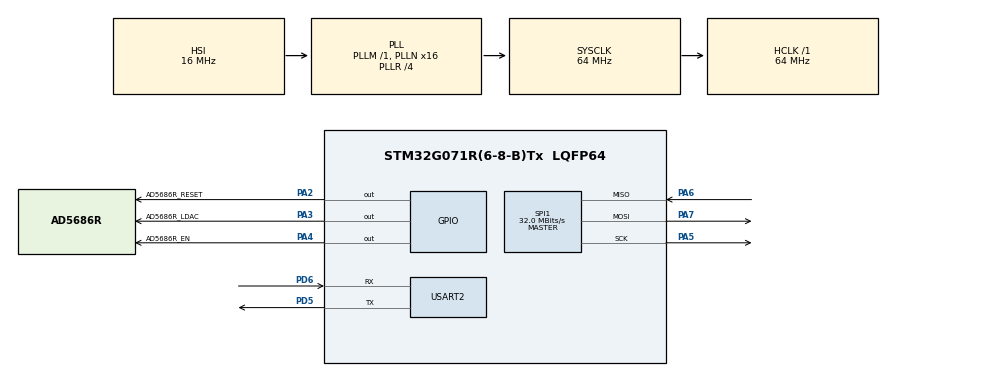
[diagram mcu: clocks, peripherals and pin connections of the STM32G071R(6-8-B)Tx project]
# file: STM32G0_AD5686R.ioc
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Mcu.Family=STM32G0
Mcu.Name=STM32G071R(6-8-B)Tx
Mcu.Package=LQFP64
PA2.GPIO_Label=AD5686R_RESET
PA2.GPIO_PuPd=GPIO_PULLUP
PA2.GPIO_Speed=GPIO_SPEED_FREQ_VERY_HIGH
PA2.PinState=GPIO_PIN_SET
PA2.Signal=GPIO_Output
PA3.GPIO_Label=AD5686R_LDAC
PA3.GPIO_PuPd=GPIO_PULLUP
PA3.GPIO_Speed=GPIO_SPEED_FREQ_VERY_HIGH
PA3.PinState=GPIO_PIN_SET
PA3.Signal=GPIO_Output
PA4.GPIO_Label=AD5686R_EN
PA4.GPIO_PuPd=GPIO_PULLUP
PA4.GPIO_Speed=GPIO_SPEED_FREQ_VERY_HIGH
PA4.PinState=GPIO_PIN_SET
PA4.Signal=GPIO_Output
PA5.GPIO_Speed=GPIO_SPEED_FREQ_VERY_HIGH
PA5.Mode=Full_Duplex_Master
PA5.Signal=SPI1_SCK
PA6.GPIO_Speed=GPIO_SPEED_FREQ_VERY_HIGH
PA6.Mode=Full_Duplex_Master
PA6.Signal=SPI1_MISO
PA7.GPIO_Speed=GPIO_SPEED_FREQ_VERY_HIGH
PA7.Mode=Full_Duplex_Master
PA7.Signal=SPI1_MOSI
PC14-OSC32_IN\ (PC14).Mode=LSE-External-Oscillator
PC14-OSC32_IN\ (PC14).Signal=RCC_OSC32_IN
PC15-OSC32_OUT\ (PC15).Mode=LSE-External-Oscillator
PC15-OSC32_OUT\ (PC15).Signal=RCC_OSC32_OUT
PD5.GPIO_Speed=GPIO_SPEED_FREQ_VERY_HIGH
PD5.Mode=Asynchronous
PD5.Signal=USART2_TX
PD6.GPIO_Speed=GPIO_SPEED_FREQ_VERY_HIGH
PD6.Mode=Asynchronous
PD6.Signal=USART2_RX
PF0-OSC_IN\ (PF0).Mode=HSE-External-Oscillator
PF0-OSC_IN\ (PF0).Signal=RCC_OSC_IN
PF1-OSC_OUT\ (PF1).Mode=HSE-External-Oscillator
PF1-OSC_OUT\ (PF1).Signal=RCC_OSC_OUT
ProjectManager.HeapSize=0x200
ProjectManager.StackSize=0x400
ProjectManager.TargetToolchain=MDK-ARM V5.27
RCC.ADCFreq_Value=64000000
RCC.AHBFreq_Value=64000000
RCC.CortexFreq_Value=64000000
RCC.EXTERNAL_CLOCK_VALUE=48000
RCC.HCLKFreq_Value=64000000
RCC.HSE_VALUE=8000000
RCC.HSI_VALUE=16000000
RCC.PLLN=16
RCC.PLLR=RCC_PLLR_DIV4
RCC.SYSCLKFreq_VALUE=64000000
RCC.SYSCLKSource=RCC_SYSCLKSOURCE_PLLCLK
RCC.VCOOutputFreq_Value=256000000
SPI1.BaudRatePrescaler=SPI_BAUDRATEPRESCALER_2
SPI1.CalculateBaudRate=32.0 MBits/s
SPI1.DataSize=SPI_DATASIZE_8BIT
SPI1.Direction=SPI_DIRECTION_2LINES
SPI1.FirstBit=SPI_FIRSTBIT_MSB
SPI1.Mode=SPI_MODE_MASTER
SPI1.VirtualType=VM_MASTER
USART2.VirtualMode-Asynchronous=VM_ASYNC
VP_SYS_VS_DBSignals.Mode=DisableDeadBatterySignals
board=custom

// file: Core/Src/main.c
/* USER CODE BEGIN Header */
/**
  ******************************************************************************
  * @file           : main.c
  * @brief          : Main program body
  ******************************************************************************
  * @attention
  *
  * <h2><center>&copy; Copyright (c) 2021 STMicroelectronics.
  * All rights reserved.</center></h2>
  *
  * This software component is licensed by ST under BSD 3-Clause license,
  * the "License"; You may not use this file except in compliance with the
  * License. You may obtain a copy of the License at:
  *                        opensource.org/licenses/BSD-3-Clause
  *
  ******************************************************************************
  */
/* USER CODE END Header */
#include "main.h"
#include "spi.h"
#include "usart.h"
#include "gpio.h"
#include "AD5686_5_4R.h"

void SystemClock_Config(void);

int main(void)
{

  /* MCU Configuration--------------------------------------------------------*/

  /* Reset of all peripherals, Initializes the Flash interface and the Systick. */
  HAL_Init();

  /* Configure the system clock */
  SystemClock_Config();

  /* Initialize all configured peripherals */
  MX_GPIO_Init();
  MX_SPI1_Init();
  MX_USART2_UART_Init();
  /* USER CODE BEGIN 2 */
	AD5686x_Init();
	AD568x_write_V(&DAC1_AD5686,Aisle_A,4.123);
  /* USER CODE END 2 */

  /* Infinite loop */
  while (1)
  {

    /* USER CODE BEGIN 3 */
		/*
		AD568x_set_shift_reg(&DAC1_AD5686,Aisle_A,0);
		AD568x_set_shift_reg(&DAC1_AD5686,Aisle_B,0);
		AD568x_Renew_LDAC(&DAC1_AD5686);
		__nop();
		AD568x_set_shift_reg(&DAC1_AD5686,Aisle_A,65535);
		AD568x_set_shift_reg(&DAC1_AD5686,Aisle_B,65535);
		AD568x_Renew_LDAC(&DAC1_AD5686);
		__nop();
		*/
		/*
		for(int i=500;i<65000;i=i+200)
		{
			AD568x_set_shift_reg(&DAC1_AD5686,Aisle_A,i);
			AD568x_set_shift_reg(&DAC1_AD5686,Aisle_B,i);
			AD568x_Renew_LDAC(&DAC1_AD5686);
			//AD568x_update_register(&DAC1_AD5686,Aisle_A);
			//AD568x_update_register(&DAC1_AD5686,Aisle_B);
		}
		for(int a=65000;a>500;a=a-200)
		{
			AD568x_set_shift_reg(&DAC1_AD5686,Aisle_A,a);
			AD568x_set_shift_reg(&DAC1_AD5686,Aisle_B,a);
			AD568x_Renew_LDAC(&DAC1_AD5686);
			//AD568x_update_register(&DAC1_AD5686,Aisle_A);
			//AD568x_update_register(&DAC1_AD5686,Aisle_B);
		}
		*/

  /* USER CODE END 3 */
}
}

void SystemClock_Config(void)
{
  RCC_OscInitTypeDef RCC_OscInitStruct = {0};
  RCC_ClkInitTypeDef RCC_ClkInitStruct = {0};
  RCC_PeriphCLKInitTypeDef PeriphClkInit = {0};

  /** Configure the main internal regulator output voltage
  */
  HAL_PWREx_ControlVoltageScaling(PWR_REGULATOR_VOLTAGE_SCALE1);
  /** Initializes the RCC Oscillators according to the specified parameters
  * in the RCC_OscInitTypeDef structure.
  */
  RCC_OscInitStruct.OscillatorType = RCC_OSCILLATORTYPE_HSI;
  RCC_OscInitStruct.HSIState = RCC_HSI_ON;
  RCC_OscInitStruct.HSIDiv = RCC_HSI_DIV1;
  RCC_OscInitStruct.HSICalibrationValue = RCC_HSICALIBRATION_DEFAULT;
  RCC_OscInitStruct.PLL.PLLState = RCC_PLL_ON;
  RCC_OscInitStruct.PLL.PLLSource = RCC_PLLSOURCE_HSI;
  RCC_OscInitStruct.PLL.PLLM = RCC_PLLM_DIV1;
  RCC_OscInitStruct.PLL.PLLN = 16;
  RCC_OscInitStruct.PLL.PLLP = RCC_PLLP_DIV2;
  RCC_OscInitStruct.PLL.PLLQ = RCC_PLLQ_DIV2;
  RCC_OscInitStruct.PLL.PLLR = RCC_PLLR_DIV4;
  if (HAL_RCC_OscConfig(&RCC_OscInitStruct) != HAL_OK)
  {
    Error_Handler();
  }
  /** Initializes the CPU, AHB and APB buses clocks
  */
  RCC_ClkInitStruct.ClockType = RCC_CLOCKTYPE_HCLK|RCC_CLOCKTYPE_SYSCLK
                              |RCC_CLOCKTYPE_PCLK1;
  RCC_ClkInitStruct.SYSCLKSource = RCC_SYSCLKSOURCE_PLLCLK;
  RCC_ClkInitStruct.AHBCLKDivider = RCC_SYSCLK_DIV1;
  RCC_ClkInitStruct.APB1CLKDivider = RCC_HCLK_DIV1;

  if (HAL_RCC_ClockConfig(&RCC_ClkInitStruct, FLASH_LATENCY_2) != HAL_OK)
  {
    Error_Handler();
  }
  /** Initializes the peripherals clocks
  */
  PeriphClkInit.PeriphClockSelection = RCC_PERIPHCLK_USART2;
  PeriphClkInit.Usart2ClockSelection = RCC_USART2CLKSOURCE_PCLK1;
  if (HAL_RCCEx_PeriphCLKConfig(&PeriphClkInit) != HAL_OK)
  {
    Error_Handler();
  }
}

void Error_Handler(void)
{
  __disable_irq();
  while (1)
  {
  }
}

/************************ (C) COPYRIGHT STMicroelectronics *****END OF FILE****/
